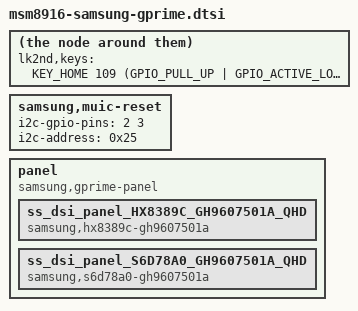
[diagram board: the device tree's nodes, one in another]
lk2nd,keys = <KEY_HOME 109 (GPIO_PULL_UP | GPIO_ACTIVE_LOW)>;

samsung,muic-reset {
	i2c-gpio-pins = <2 3>;
	i2c-address = <0x25>;
};

panel {
	compatible = "samsung,gprime-panel";

	ss_dsi_panel_HX8389C_GH9607501A_QHD {
		compatible = "samsung,hx8389c-gh9607501a";
	};

	ss_dsi_panel_S6D78A0_GH9607501A_QHD {
		compatible = "samsung,s6d78a0-gh9607501a";
	};
};
